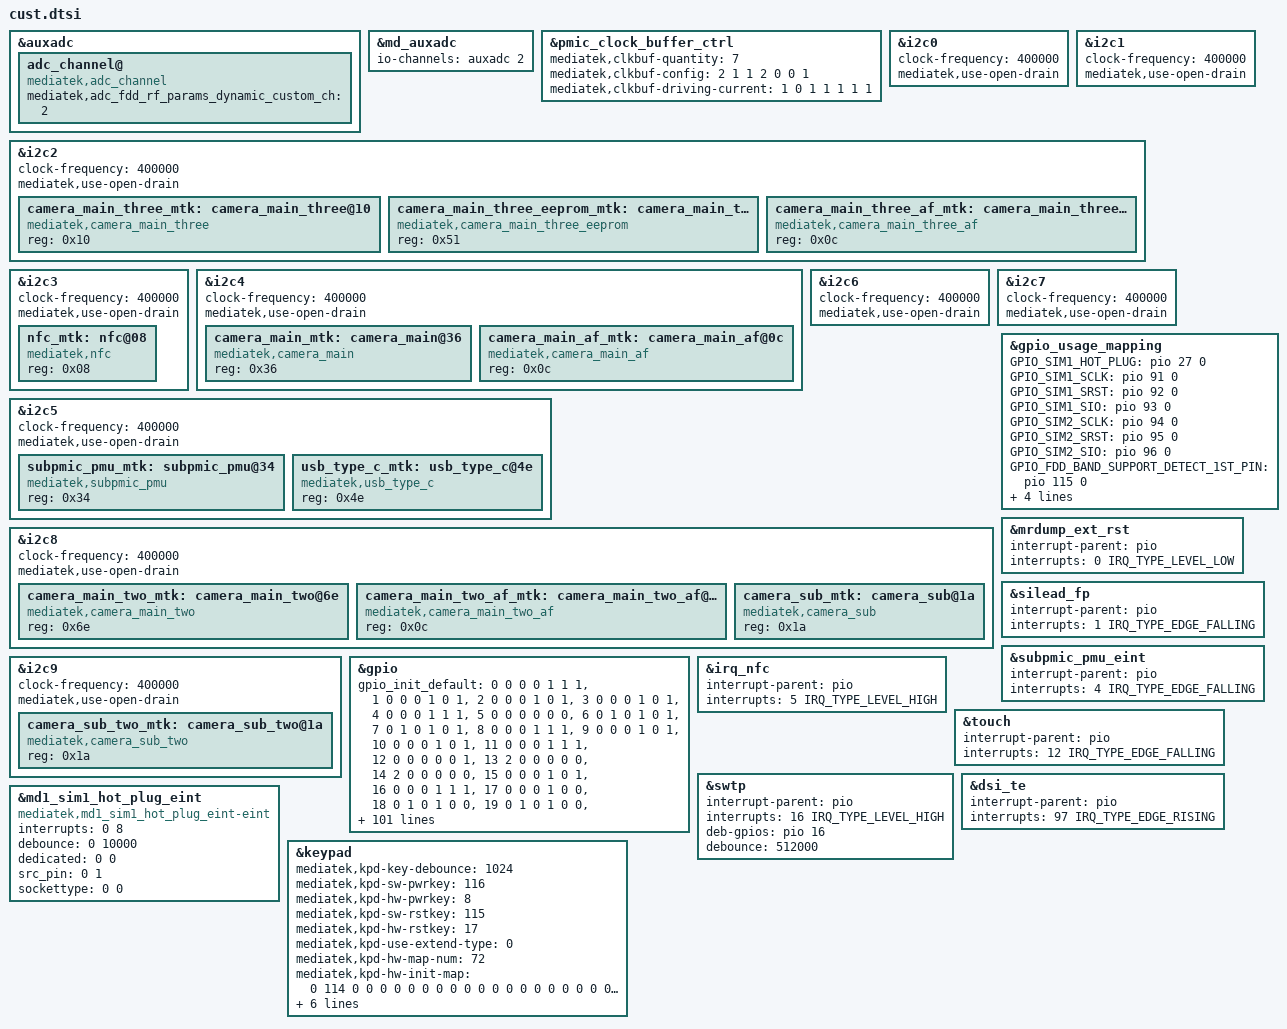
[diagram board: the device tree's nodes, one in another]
/*
 * Generated by MTK SP DrvGen Version: 3.5.160809 for MT6781.
 * 2022-11-15 19:57:26
 * Do Not Modify The File.
 * Copyright Mediatek Inc. (c) 2016.
*/

/*************************
 * ADC DTSI File
*************************/

&auxadc {
	adc_channel@ {
		compatible = "mediatek,adc_channel";
		mediatek,adc_fdd_rf_params_dynamic_custom_ch = <2>;
		status = "okay";
	};
};
&md_auxadc {
	io-channels = <&auxadc 2>;
};


/*************************
 * CLK_BUF DTSI File
*************************/

&pmic_clock_buffer_ctrl {
	mediatek,clkbuf-quantity = <7>;
	mediatek,clkbuf-config = <2 1 1 2 0 0 1>;
	mediatek,clkbuf-driving-current = <1 0 1 1 1 1 1>;
	status = "okay";
};


/*************************
 * I2C DTSI File
*************************/

&i2c0 {
	#address-cells = <1>;
	#size-cells = <0>;
	clock-frequency = <400000>;
	mediatek,use-open-drain;
};

&i2c1 {
	#address-cells = <1>;
	#size-cells = <0>;
	clock-frequency = <400000>;
	mediatek,use-open-drain;
};

&i2c2 {
	#address-cells = <1>;
	#size-cells = <0>;
	clock-frequency = <400000>;
	mediatek,use-open-drain;
	camera_main_three_mtk:camera_main_three@10 {
		compatible = "mediatek,camera_main_three";
		reg = <0x10>;
		status = "okay";
	};

	camera_main_three_eeprom_mtk:camera_main_three_eeprom@51 {
		compatible = "mediatek,camera_main_three_eeprom";
		reg = <0x51>;
		status = "okay";
	};

	camera_main_three_af_mtk:camera_main_three_af@0c {
		compatible = "mediatek,camera_main_three_af";
		reg = <0x0c>;
		status = "okay";
	};

};

&i2c3 {
	#address-cells = <1>;
	#size-cells = <0>;
	clock-frequency = <400000>;
	mediatek,use-open-drain;
	nfc_mtk:nfc@08 {
		compatible = "mediatek,nfc";
		reg = <0x08>;
		status = "okay";
	};

};

&i2c4 {
	#address-cells = <1>;
	#size-cells = <0>;
	clock-frequency = <400000>;
	mediatek,use-open-drain;
	camera_main_mtk:camera_main@36 {
		compatible = "mediatek,camera_main";
		reg = <0x36>;
		status = "okay";
	};

	camera_main_af_mtk:camera_main_af@0c {
		compatible = "mediatek,camera_main_af";
		reg = <0x0c>;
		status = "okay";
	};

};

&i2c5 {
	#address-cells = <1>;
	#size-cells = <0>;
	clock-frequency = <400000>;
	mediatek,use-open-drain;
	subpmic_pmu_mtk:subpmic_pmu@34 {
		compatible = "mediatek,subpmic_pmu";
		reg = <0x34>;
		status = "okay";
	};

	usb_type_c_mtk:usb_type_c@4e {
		compatible = "mediatek,usb_type_c";
		reg = <0x4e>;
		status = "okay";
	};

};

&i2c6 {
	#address-cells = <1>;
	#size-cells = <0>;
	clock-frequency = <400000>;
	mediatek,use-open-drain;
};

&i2c7 {
	#address-cells = <1>;
	#size-cells = <0>;
	clock-frequency = <400000>;
	mediatek,use-open-drain;
};

&i2c8 {
	#address-cells = <1>;
	#size-cells = <0>;
	clock-frequency = <400000>;
	mediatek,use-open-drain;
	camera_main_two_mtk:camera_main_two@6e {
		compatible = "mediatek,camera_main_two";
		reg = <0x6e>;
		status = "okay";
	};

	camera_main_two_af_mtk:camera_main_two_af@0c {
		compatible = "mediatek,camera_main_two_af";
		reg = <0x0c>;
		status = "okay";
	};

	camera_sub_mtk:camera_sub@1a {
		compatible = "mediatek,camera_sub";
		reg = <0x1a>;
		status = "okay";
	};

};

&i2c9 {
	#address-cells = <1>;
	#size-cells = <0>;
	clock-frequency = <400000>;
	mediatek,use-open-drain;
	camera_sub_two_mtk:camera_sub_two@1a {
		compatible = "mediatek,camera_sub_two";
		reg = <0x1a>;
		status = "okay";
	};

};



/*************************
 * GPIO DTSI File
*************************/

&gpio_usage_mapping {
	GPIO_SIM1_HOT_PLUG = <&pio 27 0>;
	GPIO_SIM1_SCLK = <&pio 91 0>;
	GPIO_SIM1_SRST = <&pio 92 0>;
	GPIO_SIM1_SIO = <&pio 93 0>;
	GPIO_SIM2_SCLK = <&pio 94 0>;
	GPIO_SIM2_SRST = <&pio 95 0>;
	GPIO_SIM2_SIO = <&pio 96 0>;
	GPIO_FDD_BAND_SUPPORT_DETECT_1ST_PIN = <&pio 115 0>;
	GPIO_FDD_BAND_SUPPORT_DETECT_2ND_PIN = <&pio 116 0>;
	GPIO_FDD_BAND_SUPPORT_DETECT_3RD_PIN = <&pio 119 0>;
};

&gpio{
	gpio_init_default = <0 0 0 0 1 1 1>,
		<1 0 0 0 1 0 1>,
		<2 0 0 0 1 0 1>,
		<3 0 0 0 1 0 1>,
		<4 0 0 0 1 1 1>,
		<5 0 0 0 0 0 0>,
		<6 0 1 0 1 0 1>,
		<7 0 1 0 1 0 1>,
		<8 0 0 0 1 1 1>,
		<9 0 0 0 1 0 1>,
		<10 0 0 0 1 0 1>,
		<11 0 0 0 1 1 1>,
		<12 0 0 0 0 0 1>,
		<13 2 0 0 0 0 0>,
		<14 2 0 0 0 0 0>,
		<15 0 0 0 1 0 1>,
		<16 0 0 0 1 1 1>,
		<17 0 0 0 1 0 0>,
		<18 0 1 0 1 0 0>,
		<19 0 1 0 1 0 0>,
		<20 0 0 0 1 0 0>,
		<21 0 0 0 1 0 0>,
		<22 0 1 0 1 0 0>,
		<23 0 0 0 1 0 0>,
		<24 0 1 0 1 0 0>,
		<25 0 0 0 1 0 0>,
		<26 0 1 0 1 0 0>,
		<27 1 0 0 1 1 0>,
		<28 0 0 0 1 0 0>,
		<29 0 0 0 1 0 0>,
		<30 0 0 0 1 0 0>,
		<31 0 0 0 1 0 0>,
		<32 1 0 0 1 1 0>,
		<33 1 0 0 0 0 0>,
		<34 1 0 0 1 1 1>,
		<35 1 0 0 0 0 1>,
		<36 1 0 0 0 0 0>,
		<37 1 0 0 0 0 0>,
		<38 0 0 0 0 0 0>,
		<39 0 0 0 0 0 0>,
		<40 1 0 0 0 0 0>,
		<41 0 1 0 1 0 0>,
		<42 0 0 0 1 1 0>,
		<43 0 0 0 1 0 0>,
		<44 2 0 0 0 0 0>,
		<45 2 0 0 0 0 1>,
		<46 2 0 0 0 0 0>,
		<47 2 0 0 1 0 0>,
		<48 4 0 0 1 1 0>,
		<49 0 1 0 1 0 0>,
		<50 4 0 0 1 1 0>,
		<51 0 1 1 1 0 0>,
		<52 1 0 0 0 0 0>,
		<53 1 0 0 0 0 0>,
		<54 1 0 0 0 0 0>,
		<55 1 0 0 0 0 0>,
		<56 0 0 0 0 0 0>,
		<57 0 0 0 1 0 0>,
		<58 0 0 0 0 0 1>,
		<59 0 0 0 0 0 1>,
		<60 3 0 0 1 0 0>,
		<61 6 0 0 1 0 0>,
		<62 6 0 0 1 1 0>,
		<63 6 0 0 1 0 0>,
		<64 6 0 0 1 0 0>,
		<65 6 0 0 1 0 0>,
		<66 0 0 0 1 0 0>,
		<67 0 0 0 1 0 0>,
		<68 0 0 0 1 0 1>,
		<69 0 0 0 1 0 1>,
		<70 0 0 0 1 0 1>,
		<71 0 0 0 1 0 1>,
		<72 0 0 0 1 0 1>,
		<73 0 0 0 1 0 1>,
		<74 0 0 0 1 0 1>,
		<75 0 0 0 1 0 1>,
		<76 0 0 0 1 0 1>,
		<77 0 0 0 1 0 1>,
		<78 0 0 0 1 0 1>,
		<79 0 0 0 1 0 1>,
		<80 1 0 0 1 1 1>,
		<81 1 0 0 1 1 1>,
		<82 3 0 0 1 0 1>,
		<83 0 0 0 1 1 1>,
		<85 1 0 0 1 0 1>,
		<86 1 0 0 1 0 1>,
		<87 1 0 0 1 0 1>,
		<88 1 0 0 1 0 1>,
		<89 1 0 0 1 0 1>,
		<90 1 0 0 1 0 1>,
		<91 1 0 0 0 0 1>,
		<92 1 0 0 0 0 1>,
		<93 1 0 0 1 1 1>,
		<94 1 0 0 0 0 1>,
		<95 1 0 0 0 0 1>,
		<96 1 0 0 1 1 1>,
		<97 1 0 0 1 0 0>,
		<98 1 0 0 0 0 1>,
		<99 0 1 0 1 0 0>,
		<100 0 0 0 1 0 0>,
		<101 1 0 0 1 0 0>,
		<102 1 0 0 1 0 0>,
		<103 1 0 0 1 0 0>,
		<104 1 0 0 1 0 0>,
		<105 1 0 0 1 0 0>,
		<106 1 0 0 1 0 0>,
		<107 1 0 0 1 0 0>,
		<108 1 0 0 1 0 1>,
		<109 1 0 0 1 0 1>,
		<110 1 0 0 1 0 1>,
		<111 1 0 0 1 0 1>,
		<112 1 0 0 1 0 1>,
		<113 1 0 0 1 0 1>,
		<114 1 0 0 1 0 1>,
		<115 0 0 0 1 0 1>,
		<116 0 0 0 1 0 1>,
		<117 0 0 0 1 0 0>,
		<118 0 0 0 1 0 0>,
		<119 0 0 0 1 0 0>,
		<120 0 0 0 1 0 0>,
		<121 0 1 0 1 0 1>,
		<122 0 0 0 1 0 1>,
		<123 0 0 0 1 0 1>,
		<124 1 0 0 1 0 0>,
		<125 0 0 0 1 0 1>,
		<126 1 0 0 1 0 0>,
		<127 1 0 0 1 0 0>,
		<128 1 0 0 1 0 0>,
		<129 1 0 0 1 0 0>,
		<130 0 0 0 1 0 0>,
		<131 0 0 0 1 0 0>,
		<132 0 0 0 1 0 0>,
		<133 0 0 0 1 0 0>,
		<134 0 0 0 1 0 0>,
		<135 0 0 0 1 0 0>,
		<136 1 0 0 1 0 0>,
		<137 1 0 0 1 0 0>,
		<138 1 0 0 1 0 0>,
		<139 1 0 0 1 0 0>,
		<140 1 0 0 1 0 0>,
		<141 1 0 0 1 0 0>,
		<142 1 0 0 1 0 0>,
		<143 1 0 0 1 1 0>,
		<144 2 0 0 0 0 1>,
		<145 2 0 0 0 0 1>,
		<146 2 0 0 1 1 1>,
		<147 2 0 0 1 1 1>,
		<148 1 0 0 1 1 1>,
		<149 1 0 0 1 1 1>,
		<150 1 0 0 1 1 1>,
		<151 1 0 0 1 1 1>,
		<152 1 0 0 1 1 1>,
		<153 1 0 0 1 1 1>,
		<154 1 0 0 1 1 1>,
		<155 1 0 0 1 1 1>,
		<156 1 0 0 1 1 1>,
		<157 1 0 0 1 1 1>,
		<158 0 0 0 1 0 1>,
		<159 0 0 0 1 0 0>,
		<160 1 0 0 1 1 1>,
		<161 1 0 0 1 1 1>,
		<162 1 0 0 1 1 1>,
		<163 1 0 0 1 1 1>,
		<164 0 1 0 1 0 1>,
		<165 0 0 0 1 0 1>,
		<166 0 0 0 1 0 1>,
		<167 0 1 0 1 0 0>,
		<168 0 1 0 1 0 1>,
		<169 0 1 0 1 0 1>,
		<170 0 0 0 0 0 1>,
		<171 0 0 0 0 0 1>,
		<172 2 0 0 1 0 1>,
		<173 0 1 0 1 0 1>,
		<174 1 0 0 0 0 1>,
		<175 1 0 0 0 0 1>,
		<176 1 0 0 1 0 1>,
		<177 1 0 0 1 0 1>,
		<178 1 0 0 0 0 0>,
		<179 1 0 0 0 0 0>,
		<180 1 0 0 0 0 1>,
		<181 1 0 0 1 0 1>,
		<182 1 0 0 0 0 0>,
		<183 1 0 0 0 0 1>,
		<184 1 0 0 0 0 1>,
		<185 1 0 0 0 0 1>,
		<186 1 0 0 0 0 1>,
		<187 1 0 0 1 0 1>,
		<188 1 0 0 1 0 1>,
		<189 1 0 0 1 0 1>,
		<190 1 0 0 1 0 1>,
		<191 0 0 0 1 0 0>,
		<192 0 0 0 1 0 0>,
		<193 0 0 0 1 0 0>,
		<194 0 0 0 1 0 0>,
		<195 0 0 0 1 0 0>,
		<196 0 0 0 1 0 0>,
		<197 0 0 0 1 0 0>,
		<198 0 0 0 1 0 0>,
		<199 0 0 0 1 0 0>,
		<200 0 0 0 1 0 0>,
		<201 0 0 0 1 0 0>,
		<202 0 0 0 1 0 0>,
		<203 0 0 0 1 0 0>,
		<204 0 0 0 1 0 0>,
		<205 0 0 0 1 0 0>,
		<206 0 0 0 1 0 0>,
		<207 0 0 0 1 0 0>,
		<208 0 0 0 1 0 0>,
		<209 0 0 0 1 0 0>,
		<210 0 0 0 1 0 0>,
		<211 0 0 0 1 0 0>,
		<212 0 0 0 1 0 0>,
		<213 0 0 0 1 0 0>,
		<214 0 0 0 1 0 0>,
		<215 0 0 0 1 0 0>,
		<216 0 0 0 1 0 0>,
		<217 0 0 0 1 0 0>,
		<218 0 0 0 1 0 0>,
		<219 0 0 0 1 0 0>,
		<220 0 0 0 1 0 0>,
		<221 0 0 0 1 0 0>;
};


/*************************
 * EINT DTSI File
*************************/

#include <dt-bindings/interrupt-controller/irq.h>
#include <dt-bindings/interrupt-controller/arm-gic.h>

&mrdump_ext_rst {
	interrupt-parent = <&pio>;
	interrupts = <0 IRQ_TYPE_LEVEL_LOW>;
	status = "okay";
};

&silead_fp {
	interrupt-parent = <&pio>;
	interrupts = <1 IRQ_TYPE_EDGE_FALLING>;
	status = "okay";
};

&subpmic_pmu_eint {
	interrupt-parent = <&pio>;
	interrupts = <4 IRQ_TYPE_EDGE_FALLING>;
	status = "okay";
};

&irq_nfc {
	interrupt-parent = <&pio>;
	interrupts = <5 IRQ_TYPE_LEVEL_HIGH>;
	status = "okay";
};

&touch {
	interrupt-parent = <&pio>;
	interrupts = <12 IRQ_TYPE_EDGE_FALLING>;
	status = "okay";
};

&swtp {
	interrupt-parent = <&pio>;
	interrupts = <16 IRQ_TYPE_LEVEL_HIGH>;
	deb-gpios = <&pio 16 0>;
	debounce = <512000>;
	status = "okay";
};

&dsi_te {
	interrupt-parent = <&pio>;
	interrupts = <97 IRQ_TYPE_EDGE_RISING>;
	status = "okay";
};



/*************************
 * MD1_EINT DTSI File
*************************/

&md1_sim1_hot_plug_eint {
	compatible = "mediatek,md1_sim1_hot_plug_eint-eint";
	interrupts = <0 8>;
	debounce = <0 10000>;
	dedicated = <0 0>;
	src_pin = <0 1>;
	sockettype = <0 0>;
	status = "okay";
};



/*************************
 * PMIC DTSI File
*************************/



/*************************
 * POWER DTSI File
*************************/



/*************************
 * KPD DTSI File
*************************/

&keypad {
	mediatek,kpd-key-debounce = <1024>;
	mediatek,kpd-sw-pwrkey = <116>;
	mediatek,kpd-hw-pwrkey = <8>;
	mediatek,kpd-sw-rstkey  = <115>;
	mediatek,kpd-hw-rstkey = <17>;
	mediatek,kpd-use-extend-type = <0>;
	/*HW Keycode [0~71] -> Linux Keycode*/
	mediatek,kpd-hw-map-num = <72>;
	mediatek,kpd-hw-init-map = <0 114 0 0 0 0 0 0 0 0 0 0 0 0 0 0 0 0 0 0 0 0 0 0 0 0 0 0 0 0 0 0 0 0 0 0 0 0 0 0 0 0 0 0 0 0 0 0 0 0 0 0 0 0 0 0 0 0 0 0 0 0 0 0 0 0 0 0 0 0 0 0 >;
	mediatek,kpd-pwrkey-eint-gpio = <0>;
	mediatek,kpd-pwkey-gpio-din  = <0>;
	mediatek,kpd-hw-dl-key0 = <17>;
	mediatek,kpd-hw-dl-key1 = <1>;
	mediatek,kpd-hw-dl-key2 = <8>;
	mediatek,kpd-hw-recovery-key = <1>;
	status = "okay";
};


